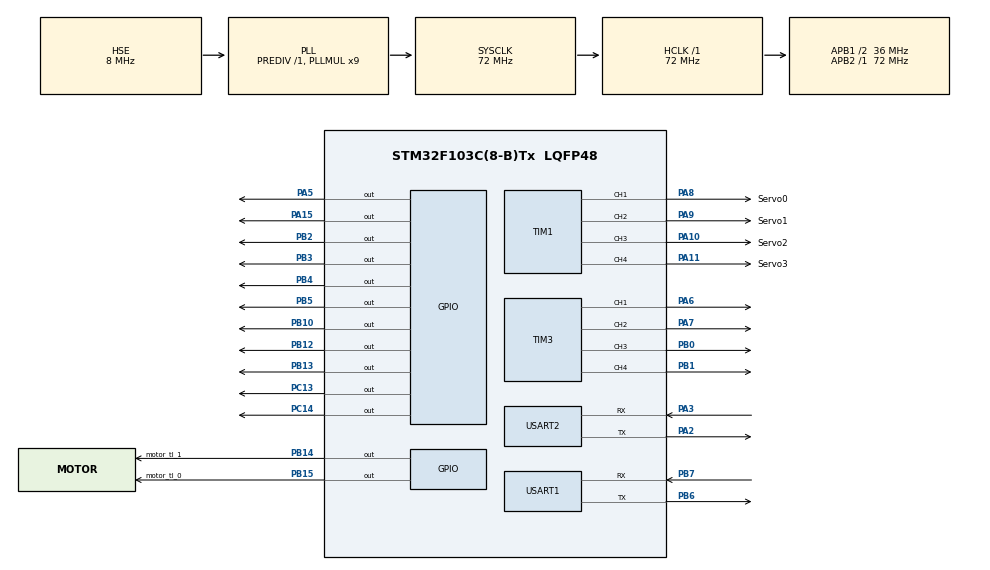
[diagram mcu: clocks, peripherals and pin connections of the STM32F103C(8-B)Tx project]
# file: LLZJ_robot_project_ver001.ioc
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Dma.Request0=USART1_RX
Dma.Request1=USART1_TX
Dma.Request2=USART2_RX
Dma.Request3=USART2_TX
Dma.USART1_RX.0.Direction=DMA_PERIPH_TO_MEMORY
Dma.USART1_RX.0.Instance=DMA1_Channel5
Dma.USART1_RX.0.MemDataAlignment=DMA_MDATAALIGN_BYTE
Dma.USART1_RX.0.MemInc=DMA_MINC_ENABLE
Dma.USART1_RX.0.Mode=DMA_NORMAL
Dma.USART1_RX.0.PeriphDataAlignment=DMA_PDATAALIGN_BYTE
Dma.USART1_RX.0.PeriphInc=DMA_PINC_DISABLE
Dma.USART1_RX.0.Priority=DMA_PRIORITY_LOW
Dma.USART1_TX.1.Direction=DMA_MEMORY_TO_PERIPH
Dma.USART1_TX.1.Instance=DMA1_Channel4
Dma.USART1_TX.1.MemDataAlignment=DMA_MDATAALIGN_BYTE
Dma.USART1_TX.1.MemInc=DMA_MINC_ENABLE
Dma.USART1_TX.1.Mode=DMA_NORMAL
Dma.USART1_TX.1.PeriphDataAlignment=DMA_PDATAALIGN_BYTE
Dma.USART1_TX.1.PeriphInc=DMA_PINC_DISABLE
Dma.USART1_TX.1.Priority=DMA_PRIORITY_LOW
Dma.USART2_RX.2.Direction=DMA_PERIPH_TO_MEMORY
Dma.USART2_RX.2.Instance=DMA1_Channel6
Dma.USART2_RX.2.MemDataAlignment=DMA_MDATAALIGN_BYTE
Dma.USART2_RX.2.MemInc=DMA_MINC_ENABLE
Dma.USART2_RX.2.Mode=DMA_NORMAL
Dma.USART2_RX.2.PeriphDataAlignment=DMA_PDATAALIGN_BYTE
Dma.USART2_RX.2.PeriphInc=DMA_PINC_DISABLE
Dma.USART2_RX.2.Priority=DMA_PRIORITY_LOW
Dma.USART2_TX.3.Direction=DMA_MEMORY_TO_PERIPH
Dma.USART2_TX.3.Instance=DMA1_Channel7
Dma.USART2_TX.3.MemDataAlignment=DMA_MDATAALIGN_BYTE
Dma.USART2_TX.3.MemInc=DMA_MINC_ENABLE
Dma.USART2_TX.3.Mode=DMA_NORMAL
Dma.USART2_TX.3.PeriphDataAlignment=DMA_PDATAALIGN_BYTE
Dma.USART2_TX.3.PeriphInc=DMA_PINC_DISABLE
Dma.USART2_TX.3.Priority=DMA_PRIORITY_LOW
FREERTOS.Queues01=Vision_CMD,32,uint16_t,0,Dynamic,NULL,NULL
FREERTOS.Tasks01=Init,24,128,RTOS_Task_Init,Default,NULL,Dynamic,NULL,NULL;Chassis,8,128,RTOS_Task_Chassis,As external,NULL,Dynamic,NULL,NULL;Remote,8,128,RTOS_Task_Remote,As external,NULL,Dynamic,NULL,NULL;Arm,8,128,RTOS_Task_Arm,As external,NULL,Dynamic,NULL,NULL
Mcu.Family=STM32F1
Mcu.Name=STM32F103C(8-B)Tx
Mcu.Package=LQFP48
NVIC.DMA1_Channel4_IRQn=true\:5\:0\:false\:false\:true\:true\:false\:true\:true
NVIC.DMA1_Channel5_IRQn=true\:5\:0\:false\:false\:true\:true\:false\:true\:true
NVIC.DMA1_Channel6_IRQn=true\:5\:0\:false\:false\:true\:true\:false\:true\:true
NVIC.DMA1_Channel7_IRQn=true\:5\:0\:false\:false\:true\:true\:false\:true\:true
NVIC.PriorityGroup=NVIC_PRIORITYGROUP_4
NVIC.TIM4_IRQn=true\:15\:0\:false\:false\:true\:false\:false\:true\:true
NVIC.TimeBase=TIM4_IRQn
NVIC.TimeBaseIP=TIM4
NVIC.USART1_IRQn=true\:5\:0\:false\:false\:true\:true\:true\:true\:true
PA10.GPIO_Label=Servo2
PA10.Signal=S_TIM1_CH3
PA11.GPIO_Label=Servo3
PA11.Signal=S_TIM1_CH4
PA13.Mode=Serial_Wire
PA13.Signal=SYS_JTMS-SWDIO
PA14.Mode=Serial_Wire
PA14.Signal=SYS_JTCK-SWCLK
PA15.Signal=GPIO_Output
PA2.Mode=Asynchronous
PA2.Signal=USART2_TX
PA3.Mode=Asynchronous
PA3.Signal=USART2_RX
PA5.GPIO_ModeDefaultOutputPP=GPIO_MODE_OUTPUT_PP
PA5.GPIO_Speed=GPIO_SPEED_FREQ_HIGH
PA5.PinState=GPIO_PIN_RESET
PA5.Signal=GPIO_Output
PA6.Signal=S_TIM3_CH1
PA7.Signal=S_TIM3_CH2
PA8.GPIO_Label=Servo0
PA8.Signal=S_TIM1_CH1
PA9.GPIO_Label=Servo1
PA9.Signal=S_TIM1_CH2
PB0.Signal=S_TIM3_CH3
PB1.Signal=S_TIM3_CH4
PB10.Signal=GPIO_Output
PB12.Signal=GPIO_Output
PB13.Signal=GPIO_Output
PB14.GPIO_Label=motor_tl_1
PB14.Signal=GPIO_Output
PB15.GPIO_Label=motor_tl_0
PB15.Signal=GPIO_Output
PB2.Signal=GPIO_Output
PB3.Signal=GPIO_Output
PB4.Signal=GPIO_Output
PB5.Signal=GPIO_Output
PB6.Mode=Asynchronous
PB6.Signal=USART1_TX
PB7.Mode=Asynchronous
PB7.Signal=USART1_RX
PC13-TAMPER-RTC.Signal=GPIO_Output
PC14-OSC32_IN.Signal=GPIO_Output
PD0-OSC_IN.Mode=HSE-External-Oscillator
PD0-OSC_IN.Signal=RCC_OSC_IN
PD1-OSC_OUT.Mode=HSE-External-Oscillator
PD1-OSC_OUT.Signal=RCC_OSC_OUT
ProjectManager.HeapSize=0x200
ProjectManager.StackSize=0x400
ProjectManager.TargetToolchain=CMake
RCC.AHBFreq_Value=72000000
RCC.APB1CLKDivider=RCC_HCLK_DIV2
RCC.APB1Freq_Value=36000000
RCC.APB1TimFreq_Value=72000000
RCC.APB2Freq_Value=72000000
RCC.APB2TimFreq_Value=72000000
RCC.HCLKFreq_Value=72000000
RCC.PLLMUL=RCC_PLL_MUL9
RCC.PLLSourceVirtual=RCC_PLLSOURCE_HSE
RCC.SYSCLKFreq_VALUE=72000000
RCC.SYSCLKSource=RCC_SYSCLKSOURCE_PLLCLK
RCC.USBFreq_Value=72000000
SH.S_TIM1_CH1.0=TIM1_CH1,PWM Generation1 CH1
SH.S_TIM1_CH2.0=TIM1_CH2,PWM Generation2 CH2
SH.S_TIM1_CH3.0=TIM1_CH3,Output Compare3 CH3
SH.S_TIM1_CH4.0=TIM1_CH4,Output Compare4 CH4
SH.S_TIM3_CH1.0=TIM3_CH1,PWM Generation1 CH1
SH.S_TIM3_CH2.0=TIM3_CH2,PWM Generation2 CH2
SH.S_TIM3_CH3.0=TIM3_CH3,PWM Generation3 CH3
SH.S_TIM3_CH4.0=TIM3_CH4,PWM Generation4 CH4
TIM1.Channel-Output\ Compare3\ CH3=TIM_CHANNEL_3
TIM1.Channel-Output\ Compare4\ CH4=TIM_CHANNEL_4
TIM1.Channel-PWM\ Generation1\ CH1=TIM_CHANNEL_1
TIM1.Channel-PWM\ Generation2\ CH2=TIM_CHANNEL_2
TIM3.Channel-PWM\ Generation1\ CH1=TIM_CHANNEL_1
TIM3.Channel-PWM\ Generation2\ CH2=TIM_CHANNEL_2
TIM3.Channel-PWM\ Generation3\ CH3=TIM_CHANNEL_3
TIM3.Channel-PWM\ Generation4\ CH4=TIM_CHANNEL_4
USART1.VirtualMode=VM_ASYNC
USART2.VirtualMode=VM_ASYNC
VP_FREERTOS_VS_CMSIS_V2.Mode=CMSIS_V2
VP_SYS_VS_tim4.Mode=TIM4
board=custom

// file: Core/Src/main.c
/* USER CODE BEGIN Header */
/**
  ******************************************************************************
  * @file           : main.c
  * @brief          : Main program body
  ******************************************************************************
  * @attention
  *
  * Copyright (c) 2026 STMicroelectronics.
  * All rights reserved.
  *
  * This software is licensed under terms that can be found in the LICENSE file
  * in the root directory of this software component.
  * If no LICENSE file comes with this software, it is provided AS-IS.
  *
  ******************************************************************************
  */
/* USER CODE END Header */
#include "main.h"
#include "cmsis_os.h"
#include "dma.h"
#include "tim.h"
#include "usart.h"
#include "gpio.h"

void SystemClock_Config(void);
void MX_FREERTOS_Init(void);

int main(void)
{

  /* MCU Configuration--------------------------------------------------------*/

  /* Reset of all peripherals, Initializes the Flash interface and the Systick. */
  HAL_Init();

  /* Configure the system clock */
  SystemClock_Config();

  /* Initialize all configured peripherals */
  MX_GPIO_Init();
  MX_DMA_Init();
  MX_USART1_UART_Init();
  MX_TIM3_Init();
  MX_USART2_UART_Init();
  MX_TIM1_Init();

  /* Init scheduler */
  osKernelInitialize();  /* Call init function for freertos objects (in cmsis_os2.c) */
  MX_FREERTOS_Init();

  /* Start scheduler */
  osKernelStart();

  /* We should never get here as control is now taken by the scheduler */

  /* Infinite loop */
  while (1)
  {

  }
}

void SystemClock_Config(void)
{
  RCC_OscInitTypeDef RCC_OscInitStruct = {0};
  RCC_ClkInitTypeDef RCC_ClkInitStruct = {0};

  /** Initializes the RCC Oscillators according to the specified parameters
  * in the RCC_OscInitTypeDef structure.
  */
  RCC_OscInitStruct.OscillatorType = RCC_OSCILLATORTYPE_HSE;
  RCC_OscInitStruct.HSEState = RCC_HSE_ON;
  RCC_OscInitStruct.HSEPredivValue = RCC_HSE_PREDIV_DIV1;
  RCC_OscInitStruct.HSIState = RCC_HSI_ON;
  RCC_OscInitStruct.PLL.PLLState = RCC_PLL_ON;
  RCC_OscInitStruct.PLL.PLLSource = RCC_PLLSOURCE_HSE;
  RCC_OscInitStruct.PLL.PLLMUL = RCC_PLL_MUL9;
  if (HAL_RCC_OscConfig(&RCC_OscInitStruct) != HAL_OK)
  {
    Error_Handler();
  }

  /** Initializes the CPU, AHB and APB buses clocks
  */
  RCC_ClkInitStruct.ClockType = RCC_CLOCKTYPE_HCLK|RCC_CLOCKTYPE_SYSCLK
                              |RCC_CLOCKTYPE_PCLK1|RCC_CLOCKTYPE_PCLK2;
  RCC_ClkInitStruct.SYSCLKSource = RCC_SYSCLKSOURCE_PLLCLK;
  RCC_ClkInitStruct.AHBCLKDivider = RCC_SYSCLK_DIV1;
  RCC_ClkInitStruct.APB1CLKDivider = RCC_HCLK_DIV2;
  RCC_ClkInitStruct.APB2CLKDivider = RCC_HCLK_DIV1;

  if (HAL_RCC_ClockConfig(&RCC_ClkInitStruct, FLASH_LATENCY_2) != HAL_OK)
  {
    Error_Handler();
  }
}

void HAL_TIM_PeriodElapsedCallback(TIM_HandleTypeDef *htim)
{
  if (htim->Instance == TIM4)
  {
    HAL_IncTick();
  }
}

void Error_Handler(void)
{
  __disable_irq();
  while (1)
  {
  }
}

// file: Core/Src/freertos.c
/* USER CODE BEGIN Header */
/**
  ******************************************************************************
  * File Name          : freertos.c
  * Description        : Code for freertos applications
  ******************************************************************************
  * @attention
  *
  * Copyright (c) 2026 STMicroelectronics.
  * All rights reserved.
  *
  * This software is licensed under terms that can be found in the LICENSE file
  * in the root directory of this software component.
  * If no LICENSE file comes with this software, it is provided AS-IS.
  *
  ******************************************************************************
  */
/* USER CODE END Header */

#include "FreeRTOS.h"
#include "task.h"
#include "main.h"
#include "cmsis_os.h"

/* Definitions for Init */
osThreadId_t InitHandle;
const osThreadAttr_t Init_attributes = {
  .name = "Init",
  .stack_size = 128 * 4,
  .priority = (osPriority_t) osPriorityNormal,
};
/* Definitions for Chassis */
osThreadId_t ChassisHandle;
const osThreadAttr_t Chassis_attributes = {
  .name = "Chassis",
  .stack_size = 128 * 4,
  .priority = (osPriority_t) osPriorityLow,
};
/* Definitions for Remote */
osThreadId_t RemoteHandle;
const osThreadAttr_t Remote_attributes = {
  .name = "Remote",
  .stack_size = 128 * 4,
  .priority = (osPriority_t) osPriorityLow,
};
/* Definitions for Arm */
osThreadId_t ArmHandle;
const osThreadAttr_t Arm_attributes = {
  .name = "Arm",
  .stack_size = 128 * 4,
  .priority = (osPriority_t) osPriorityLow,
};
/* Definitions for Vision_CMD */
osMessageQueueId_t Vision_CMDHandle;
const osMessageQueueAttr_t Vision_CMD_attributes = {
  .name = "Vision_CMD"
};

void RTOS_Task_Init(void *argument);
extern void RTOS_Task_Chassis(void *argument);
extern void RTOS_Task_Remote(void *argument);
extern void RTOS_Task_Arm(void *argument);

void MX_FREERTOS_Init(void); /* (MISRA C 2004 rule 8.1) */

void MX_FREERTOS_Init(void) {

  /* Create the queue(s) */
  /* creation of Vision_CMD */
  Vision_CMDHandle = osMessageQueueNew (32, sizeof(uint16_t), &Vision_CMD_attributes);

  /* Create the thread(s) */
  /* creation of Init */
  InitHandle = osThreadNew(RTOS_Task_Init, NULL, &Init_attributes);

  /* creation of Chassis */
  ChassisHandle = osThreadNew(RTOS_Task_Chassis, NULL, &Chassis_attributes);

  /* creation of Remote */
  RemoteHandle = osThreadNew(RTOS_Task_Remote, NULL, &Remote_attributes);

  /* creation of Arm */
  ArmHandle = osThreadNew(RTOS_Task_Arm, NULL, &Arm_attributes);

}

void RTOS_Task_Init(void *argument)
{
  /* USER CODE BEGIN RTOS_Task_Init */
  /* Infinite loop */
  for(;;)
  {
    HAL_GPIO_TogglePin(GPIOA, GPIO_PIN_5);
    osDelay(1000);
  }
  /* USER CODE END RTOS_Task_Init */
}
